# STM32G411xC register map
File version: 1.0
Registers are 32-bit, read-write, reset 0x0 unless marked. A register's access mark holds for its fields unless they carry their own. Offsets are from the block's base; [hi:lo] are bit positions; lines under a group give offsets from that group; {n}, {i} and the like mark numbered series.

## CRC — CRC calculation unit
Base 0x40023000
0x00 DR — CRC Data register
  [31:0] DR — Data register bits
0x04 IDR — CRC Independent data register
  [31:0] IDR — General-purpose 32-bit data register bits
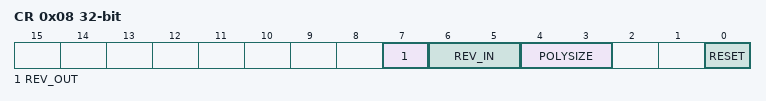
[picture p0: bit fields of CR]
0x08 CR — CRC Control register
  [7] REV_OUT — REV_OUT Reverse Output Data bits
    0=NONE (Output Data bit order not affected); 1=BIT (Output Data bit reversal done by bit)
  [6:5] REV_IN — REV_IN Reverse Input Data bits
    0=NONE (Input Data bit order not affected); 1=BYTE (Input Data bit reversal done by byte); 2=HALFWORD (Input Data bit reversal done by half-word); 3=WORD (Input Data bit reversal done by word)
  [4:3] POLYSIZE — Polynomial size bits
    0=POLYLENGTH_32B (32 bits Polynomial size); 1=POLYLENGTH_16B (16 bits Polynomial size); 2=POLYLENGTH_8B (8 bits Polynomial size); 3=POLYLENGTH_7B (7 bits Polynomial size)
  [0] RESET — RESET the CRC computation unit bit
0x10 INIT — Initial CRC value register
  [31:0] INIT — Initial CRC value bits
0x14 POL — CRC polynomial register
  [31:0] POL — Coefficients of the polynomial

## GPIOA — General Purpose I/O
Base 0x48000000
Same registers: GPIOB 0x48000400, GPIOC 0x48000800, GPIOD 0x48000C00, GPIOE 0x48001000, GPIOF 0x48001400, GPIOG 0x48001800
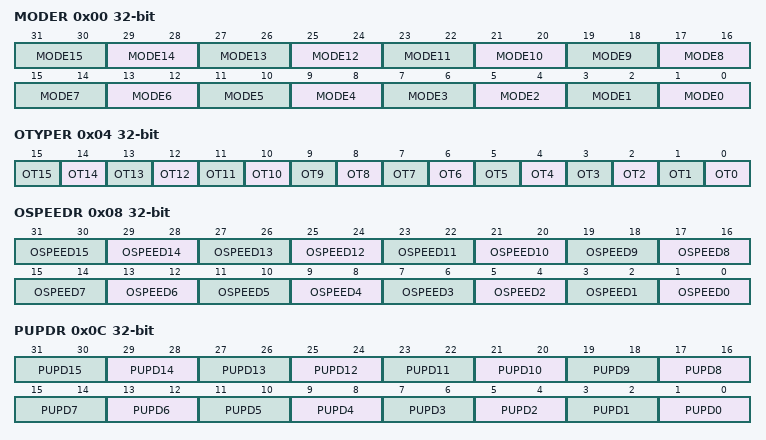
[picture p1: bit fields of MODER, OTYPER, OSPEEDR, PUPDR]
0x00 MODER — GPIO port mode register
  [2n+1:2n] MODE{n} (n=0..15)
0x04 OTYPER — GPIO port output type register
  [n] OT{n} (n=0..15)
0x08 OSPEEDR — GPIO port output speed register
  [2n+1:2n] OSPEED{n} (n=0..15)
0x0C PUPDR — GPIO port pull-up/pull-down register
  [2n+1:2n] PUPD{n} (n=0..15)
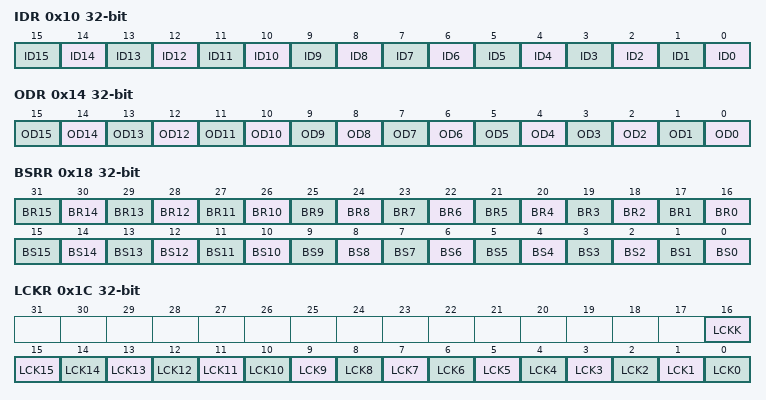
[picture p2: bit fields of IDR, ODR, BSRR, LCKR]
0x10 IDR — GPIO port input data register
  [n] ID{n} (n=0..15)
0x14 ODR — GPIO port output data register
  [n] OD{n} (n=0..15)
0x18 BSRR — GPIO port bit set/reset register
  [n+16] BR{n} (n=0..15), [n] BS{n} (n=0..15)
0x1C LCKR — GPIO port configuration lock register
  [16] LCKK, [n] LCK{n} (n=0..15)
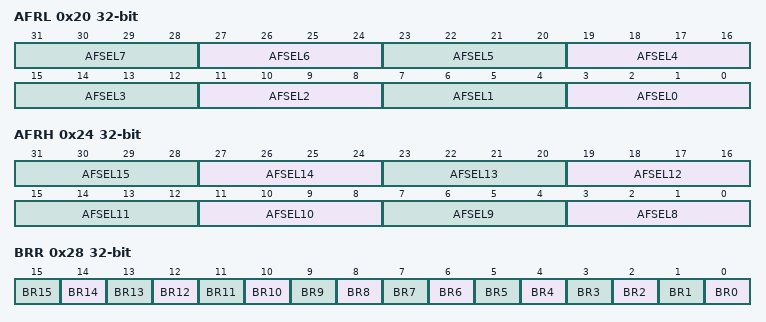
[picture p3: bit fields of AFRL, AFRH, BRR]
0x20 AFRL — GPIO alternate function registers
  [4n+3:4n] AFSEL{n} (n=0..7)
0x24 AFRH — GPIO alternate function registers
  [4n-29:4n-32] AFSEL{n} (n=8..15)
0x28 BRR — GPIO Bit Reset register
  [n] BR{n} (n=0..15)

## ADC12_COMMON
Base 0x50000300
Same registers: ADC345_COMMON 0x50000700
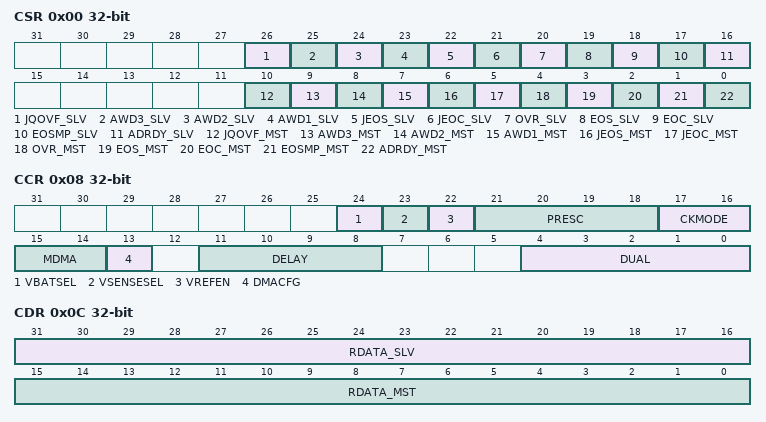
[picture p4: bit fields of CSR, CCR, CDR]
0x00 CSR — ADC common status register
  [26] JQOVF_SLV — ADC multimode slave group injected contexts queue overflow flag
  [25] AWD3_SLV — ADC multimode slave analog watchdog 3 flag
  [24] AWD2_SLV — ADC multimode slave analog watchdog 2 flag
  [23] AWD1_SLV — ADC multimode slave analog watchdog 1 flag
  [22] JEOS_SLV — ADC multimode slave group injected end of sequence conversions flag
  [21] JEOC_SLV — ADC multimode slave group injected end of unitary conversion flag
  [20] OVR_SLV — ADC multimode slave group regular overrun flag
  [19] EOS_SLV — ADC multimode slave group regular end of sequence conversions flag
  [18] EOC_SLV — ADC multimode slave group regular end of unitary conversion flag
  [17] EOSMP_SLV — ADC multimode slave group regular end of sampling flag
  [16] ADRDY_SLV — ADC multimode slave ready flag
  [10] JQOVF_MST — ADC multimode master group injected contexts queue overflow flag
  [9] AWD3_MST — ADC multimode master analog watchdog 3 flag
  [8] AWD2_MST — ADC multimode master analog watchdog 2 flag
  [7] AWD1_MST — ADC multimode master analog watchdog 1 flag
  [6] JEOS_MST — ADC multimode master group injected end of sequence conversions flag
  [5] JEOC_MST — ADC multimode master group injected end of unitary conversion flag
  [4] OVR_MST — ADC multimode master group regular overrun flag
  [3] EOS_MST — ADC multimode master group regular end of sequence conversions flag
  [2] EOC_MST — ADC multimode master group regular end of unitary conversion flag
  [1] EOSMP_MST — ADC multimode master group regular end of sampling flag
  [0] ADRDY_MST — ADC multimode master ready flag
0x08 CCR — ADC common configuration register
  [24] VBATSEL — ADC internal path to battery voltage enable
  [23] VSENSESEL — ADC internal path to temperature sensor enable
  [22] VREFEN — ADC internal path to VrefInt enable
  [21:18] PRESC — ADC common clock prescaler, only for clock source asynchronous
  [17:16] CKMODE — ADC common clock source and prescaler (prescaler only for clock source synchronous)
  [15:14] MDMA — ADC multimode DMA transfer enable
  [13] DMACFG — ADC multimode DMA transfer configuration
  [11:8] DELAY — ADC multimode delay between 2 sampling phases
    0=DELAY_1CYCLE; {v}=DELAY_{v+1}CYCLES (v=1..11)
  [4:0] DUAL — ADC multimode mode selection
    0=INDEPENDENT; 6=DUAL_REG_SIMULT; 7=DUAL_REG_INTERL; 5=DUAL_INJ_SIMULT; 9=DUAL_INJ_ALTERN; 1=DUAL_REG_SIM_INJ_SIM; 2=DUAL_REG_SIM_INJ_ALT; 3=DUAL_REG_INT_INJ_SIM
0x0C CDR — ADC common group regular data register
  [31:16] RDATA_SLV — ADC multimode slave group regular conversion data
  [15:0] RDATA_MST — ADC multimode master group regular conversion data

## RNG
Base 0x50060800
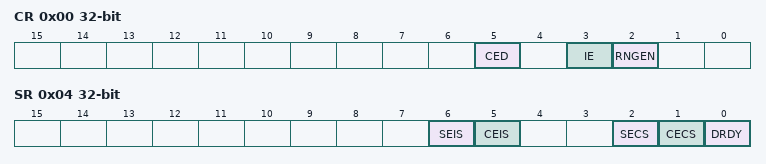
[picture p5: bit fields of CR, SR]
0x00 CR — RNG control register
  [5] CED, [3] IE, [2] RNGEN
0x04 SR — RNG status register
  [6] SEIS, [5] CEIS, [2] SECS, [1] CECS, [0] DRDY
0x08 DR — RNG data register

## DBGMCU — Debug MCU
Base 0xE0042000
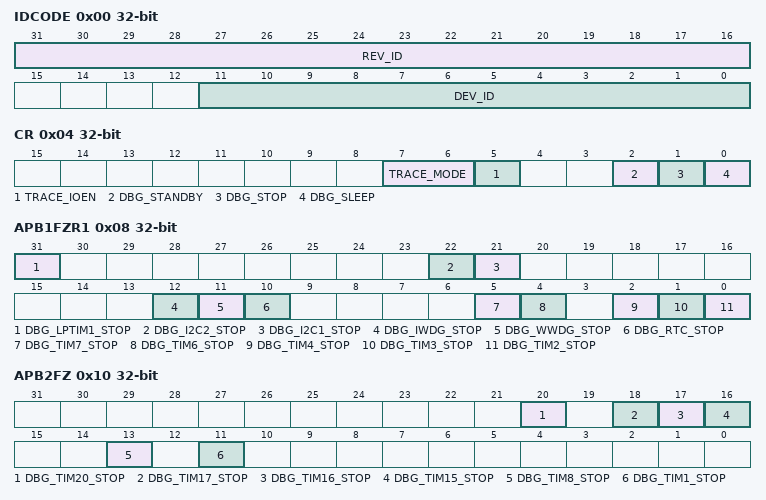
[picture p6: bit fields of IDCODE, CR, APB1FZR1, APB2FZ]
0x00 IDCODE — MCU device ID code
  [31:16] REV_ID, [11:0] DEV_ID
0x04 CR — Debug MCU configuration register
  [7:6] TRACE_MODE, [5] TRACE_IOEN, [2] DBG_STANDBY, [1] DBG_STOP, [0] DBG_SLEEP
0x08 APB1FZR1 — Debug MCU APB1 freeze register 1
  [31] DBG_LPTIM1_STOP, [22] DBG_I2C2_STOP, [21] DBG_I2C1_STOP, [12] DBG_IWDG_STOP, [11] DBG_WWDG_STOP, [10] DBG_RTC_STOP, [5] DBG_TIM7_STOP, [4] DBG_TIM6_STOP, [2] DBG_TIM4_STOP, [1] DBG_TIM3_STOP, [0] DBG_TIM2_STOP
0x0C APB1FZR2 — Debug MCU APB1 freeze register 2
0x10 APB2FZ — Debug MCU APB2 freeze register
  [20] DBG_TIM20_STOP, [18] DBG_TIM17_STOP, [17] DBG_TIM16_STOP, [16] DBG_TIM15_STOP, [13] DBG_TIM8_STOP, [11] DBG_TIM1_STOP
